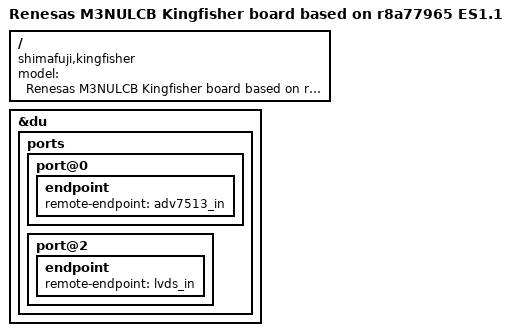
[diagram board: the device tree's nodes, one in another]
/*
 * Device Tree Source for the M3NULCB Kingfisher board
 *
 * Copyright (C) 2017 Renesas Electronics Corp.
 * Copyright (C) 2017 Cogent Embedded, Inc.
 *
 * This file is licensed under the terms of the GNU General Public License
 * version 2.  This program is licensed "as is" without any warranty of any
 * kind, whether express or implied.
 */

#include "r8a77965-m3nulcb.dts"
#include "ulcb-kf.dtsi"

/ {
	model = "Renesas M3NULCB Kingfisher board based on r8a77965 ES1.1";
	compatible = "shimafuji,kingfisher", "renesas,m3nulcb",
		     "renesas,r8a77965";
};

&du {
	ports {
		port@0 {
			endpoint {
				remote-endpoint = <&adv7513_in>;
			};
		};
		port@2 {
			endpoint {
				remote-endpoint = <&lvds_in>;
			};
		};
	};
};
